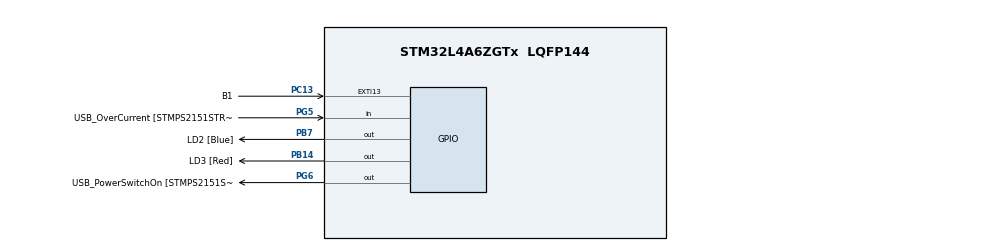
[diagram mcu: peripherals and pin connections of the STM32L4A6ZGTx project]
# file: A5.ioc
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Mcu.Family=STM32L4
Mcu.Name=STM32L4A6ZGTx
Mcu.Package=LQFP144
NVIC.PriorityGroup=NVIC_PRIORITYGROUP_4
PA10.GPIO_Label=USB_ID
PA10.Signal=USB_OTG_FS_ID
PA11.GPIO_Label=USB_DM
PA11.Signal=USB_OTG_FS_DM
PA12.GPIO_Label=USB_DP
PA12.Signal=USB_OTG_FS_DP
PA13\ (JTMS/SWDIO).GPIO_Label=TMS
PA13\ (JTMS/SWDIO).Mode=Trace_Asynchronous_SW
PA13\ (JTMS/SWDIO).Signal=SYS_JTMS-SWDIO
PA14\ (JTCK/SWCLK).GPIO_Label=TCK
PA14\ (JTCK/SWCLK).Mode=Trace_Asynchronous_SW
PA14\ (JTCK/SWCLK).Signal=SYS_JTCK-SWCLK
PA8.GPIO_Label=USB_SOF [TP1]
PA8.Signal=USB_OTG_FS_SOF
PA9.GPIO_Label=USB_VBUS
PA9.Signal=USB_OTG_FS_VBUS
PB14.GPIO_Label=LD3 [Red]
PB14.Signal=GPIO_Output
PB3\ (JTDO/TRACESWO).GPIO_Label=SWO
PB3\ (JTDO/TRACESWO).Mode=Trace_Asynchronous_SW
PB3\ (JTDO/TRACESWO).Signal=SYS_JTDO-SWO
PB7.GPIO_Label=LD2 [Blue]
PB7.Signal=GPIO_Output
PC13.GPIO_Label=B1
PC13.Signal=GPXTI13
PC14-OSC32_IN\ (PC14).Signal=RCC_OSC32_IN
PC15-OSC32_OUT\ (PC15).Signal=RCC_OSC32_OUT
PG5.GPIO_Label=USB_OverCurrent [STMPS2151STR_FAULT]
PG5.Signal=GPIO_Input
PG6.GPIO_Label=USB_PowerSwitchOn [STMPS2151STR_EN]
PG6.Signal=GPIO_Output
PG7.GPIO_Label=STLK_RX [STM32F103CBT6_PA3]
PG7.Signal=LPUART1_TX
PG8.GPIO_Label=STLK_TX [STM32F103CBT6_PA2]
PG8.Signal=LPUART1_RX
PH1-OSC_OUT\ (PH1).Signal=RCC_OSC_OUT
ProjectManager.HeapSize=0x200
ProjectManager.StackSize=0x400
ProjectManager.TargetToolchain=STM32CubeIDE
RCC.APB1CLKDivider=RCC_HCLK_DIV2
RCC.APB1Freq_Value=2000000
RCC.APB1TimFreq_Value=4000000
RCC.HSE_VALUE=8000000
RCC.HSI48_VALUE=48000000
RCC.HSI_VALUE=16000000
RCC.LSE_VALUE=32768
RCC.MSI_VALUE=4000000
RCC.VCOOutputFreq_Value=32000000
board=NUCLEO-L4A6ZG

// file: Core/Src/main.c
/* USER CODE BEGIN Header */
/*******************************************************************************
 * EE 329 A5: SPI based DAC
 *******************************************************************************
 * @file           : main.c
 * @brief          : This is a programmable voltage output leveraging the SPI
 * 					bus on the STM32 and the MCP4281
 * project         : EE 329 S'24 Assignment 5
 * authors         : Raheel Rehmatullah and Colin Lucio
 * version         : 1
 * date            : 5_17_2024
 * compiler        : STM32CubeIDE v.1.15.0
 * target          : NUCLEO-L4A6ZG
 * clocks          : 4 MHz MSI to AHB2
 * @attention      : (c) 2023 STMicroelectronics.  All rights reserved.
 *******************************************************************************
/* USER CODE END Header */
#include "main.h"
#include "dac.h"
#include "keypad.h"

void SystemClock_Config(void);
void setup_user_LEDs_PBSW(void);
int ginumRecv = 0;
int giNumFlag = 0;

int main(void)
{
 HAL_Init();
 SystemClock_Config();
 Keypad_Init();
 setup_user_LEDs_PBSW();
 DAC_Init();
 DAC_write(0);
 int iVoltage = 0;
 int iCount = 0;
 uint8_t keyPressed;
 uint8_t lastKeyPressed;

 while (1)
 {
	 keyPressed = Keypad_Read();

	 if ( (keyPressed != lastKeyPressed) && (keyPressed != '\0') && (keyPressed != '*') ){
		 ginumRecv = keyPressed & 0x0F;
			  switch( iCount ) {
			  case 0:
				  //Voltage value ones place
				  iVoltage += ( 1000 * ginumRecv );
				  iCount++;
				  break;
			  case 1:
				  //voltage value in hundreds of mV
				  iVoltage += ( 100 * ginumRecv );
				  iCount++;
				  break;
			  case 2:
				  //voltage value in tens of mV
				  iVoltage += ( 10 * ginumRecv );
				  iCount++;
				  break;
			  default:
				  break;
			  }
		  }

		  if ( (keyPressed == '*') && (keyPressed != lastKeyPressed) ){
			  iCount = 0;
			  iVoltage = 0;
			  GPIOB->ODR &= ~GPIO_PIN_7;
		  }

		  //User has finished inputting desired voltage (in mV)
	 	  if(iCount >= 3){
	 		 GPIOB->ODR |= GPIO_PIN_7;
	 		  if ((iVoltage <= 3300) && (iVoltage != 0) ){
				  dac_data_type iDacVolt = DAC_volt_conv( iVoltage );
				  DAC_write( iDacVolt );
	 		  }
	 		  else if (iVoltage == 0){
				  DAC_write( 0 );
	 		  }
	 		  else if (iVoltage > 3300){
					  DAC_write( 3300 );
		 		  }
	 		  else {
					  dac_data_type iDacVolt = DAC_volt_conv( iVoltage );
					  DAC_write( iVoltage );
			  }

	 	  }
	 	lastKeyPressed = keyPressed;
	  }

}
void SystemClock_Config(void)
{
 RCC_OscInitTypeDef RCC_OscInitStruct = {0};
 RCC_ClkInitTypeDef RCC_ClkInitStruct = {0};
 /** Configure the main internal regulator output voltage
 */
 if (HAL_PWREx_ControlVoltageScaling(PWR_REGULATOR_VOLTAGE_SCALE1) != HAL_OK)
 {
   Error_Handler();
 }
 /** Initializes the RCC Oscillators according to the specified parameters
 * in the RCC_OscInitTypeDef structure.
 */
 RCC_OscInitStruct.OscillatorType = RCC_OSCILLATORTYPE_MSI;
 RCC_OscInitStruct.MSIState = RCC_MSI_ON;
 RCC_OscInitStruct.MSICalibrationValue = 0;
 RCC_OscInitStruct.MSIClockRange = RCC_MSIRANGE_6;
 RCC_OscInitStruct.PLL.PLLState = RCC_PLL_NONE;
 if (HAL_RCC_OscConfig(&RCC_OscInitStruct) != HAL_OK)
 {
   Error_Handler();
 }
 /** Initializes the CPU, AHB and APB buses clocks
 */
 RCC_ClkInitStruct.ClockType = RCC_CLOCKTYPE_HCLK|RCC_CLOCKTYPE_SYSCLK
                             |RCC_CLOCKTYPE_PCLK1|RCC_CLOCKTYPE_PCLK2;
 RCC_ClkInitStruct.SYSCLKSource = RCC_SYSCLKSOURCE_MSI;
 RCC_ClkInitStruct.AHBCLKDivider = RCC_SYSCLK_DIV1;
 RCC_ClkInitStruct.APB1CLKDivider = RCC_HCLK_DIV2;
 RCC_ClkInitStruct.APB2CLKDivider = RCC_HCLK_DIV1;
 if (HAL_RCC_ClockConfig(&RCC_ClkInitStruct, FLASH_LATENCY_0) != HAL_OK)
 {
   Error_Handler();
 }
}
/* USER CODE BEGIN 4 */

void setup_user_LEDs_PBSW(void) {
	RCC->AHB2ENR |= ( RCC_AHB2ENR_GPIOBEN |
					  RCC_AHB2ENR_GPIOCEN );
	GPIOB->MODER &= ~GPIO_MODER_MODE7;
	GPIOB->MODER |= GPIO_MODER_MODE7_0;
	GPIOB->OTYPER &= ~GPIO_OTYPER_OT7;
	GPIOB->PUPDR &= ~GPIO_PUPDR_PUPD7;
	GPIOB->OSPEEDR |= ( 3 << GPIO_OSPEEDR_OSPEED7_Pos );
	GPIOB->BRR |= GPIO_PIN_7;
	GPIOC->MODER &= ~GPIO_MODER_MODE13;
	GPIOC->PUPDR &= ~GPIO_PUPDR_PUPD13;
	GPIOC->PUPDR |= GPIO_PUPDR_PUPD13_1;
}
/* USER CODE END 4 */
void Error_Handler(void)
{
 __disable_irq();
 while (1)
 {
 }
}
